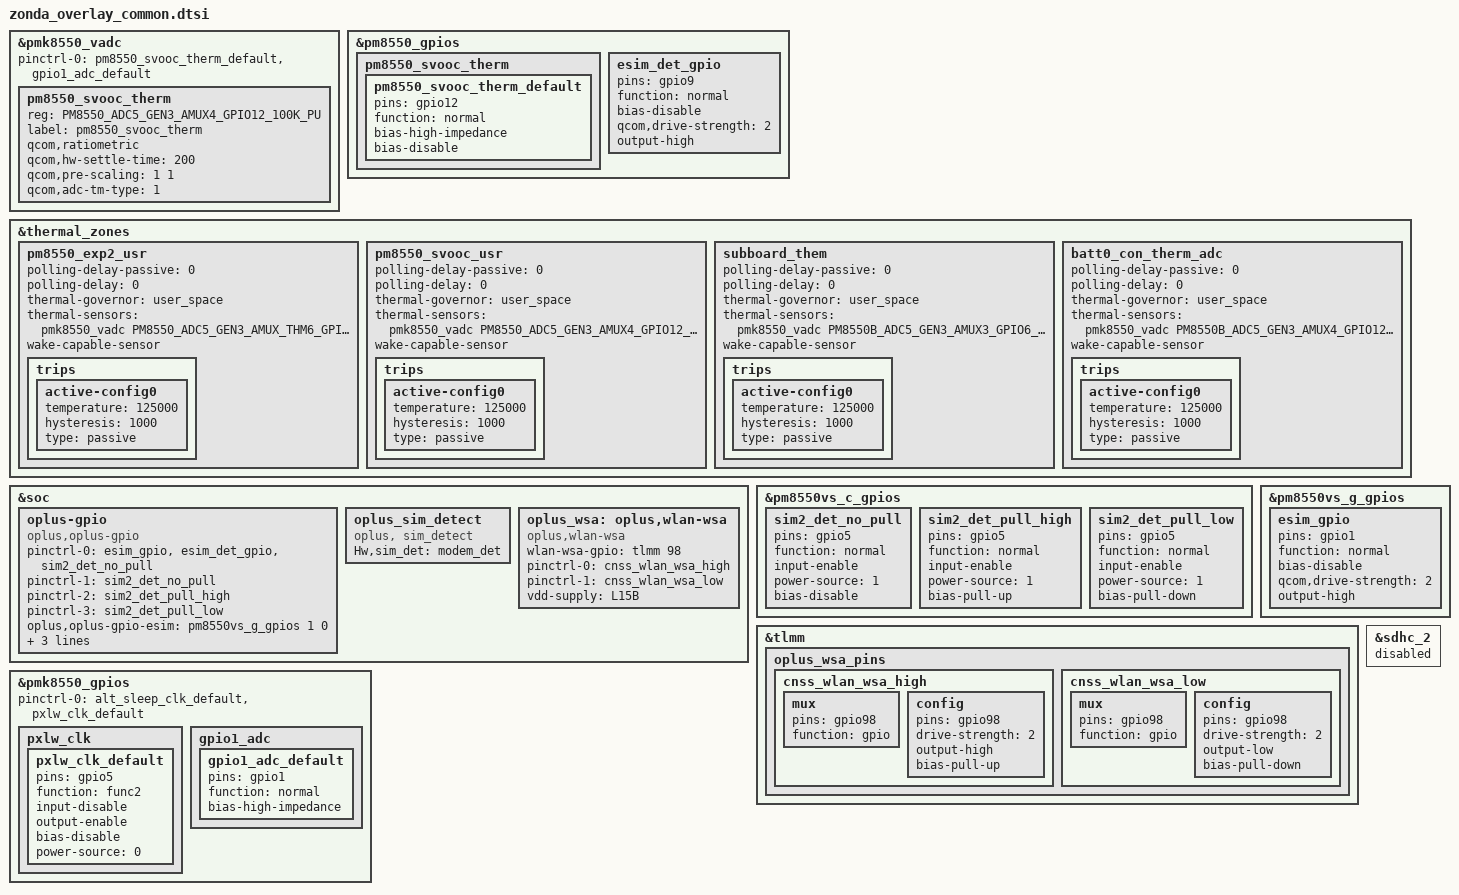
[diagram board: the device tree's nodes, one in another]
// Add the thermistors of explorer and svooc
&pmk8550_vadc {
	pinctrl-0 = <&pm8550_svooc_therm_default &gpio1_adc_default>;
	pinctrl-names = "default";

	pm8550_svooc_therm {
		reg = <PM8550_ADC5_GEN3_AMUX4_GPIO12_100K_PU>;
		label = "pm8550_svooc_therm";
		qcom,ratiometric;
		qcom,hw-settle-time = <200>;
		qcom,pre-scaling = <1 1>;
		qcom,adc-tm-type = <1>;
	};
};

&pm8550_gpios {
	pm8550_svooc_therm {
		pm8550_svooc_therm_default: pm8550_svooc_therm_default {
			pins = "gpio12";
			function = "normal"; //normal
			bias-high-impedance;
			bias-disable;
		};
	};
};
/*
&pmk8550_vadc {
	pm8550_exp2_therm {
		reg = <PM8550_ADC5_GEN3_AMUX_THM6_GPIO2_100K_PU>;
		label = "pm8550_exp2_therm";
		qcom,ratiometric;
		qcom,hw-settle-time = <200>;
		qcom,pre-scaling = <1 1>;
		qcom,adc-tm-type = <1>;
	};
};
*/
&thermal_zones {
	pm8550_exp2_usr {
		polling-delay-passive = <0>;
		polling-delay = <0>;
		thermal-governor = "user_space";
		thermal-sensors = <&pmk8550_vadc PM8550_ADC5_GEN3_AMUX_THM6_GPIO2_100K_PU>;
		wake-capable-sensor;
		trips {
			active-config0 {
				temperature = <125000>;
				hysteresis = <1000>;
				type = "passive";
			};
		};
	};

	pm8550_svooc_usr {
		polling-delay-passive = <0>;
		polling-delay = <0>;
		thermal-governor = "user_space";
		thermal-sensors = <&pmk8550_vadc PM8550_ADC5_GEN3_AMUX4_GPIO12_100K_PU>;
		wake-capable-sensor;
		trips {
			active-config0 {
				temperature = <125000>;
				hysteresis = <1000>;
				type = "passive";
			};
		};
	};
};

//#ifdef OPLUS_FEATURE_CHG_BASIC
&thermal_zones {
	subboard_them {
		polling-delay-passive = <0>;
		polling-delay = <0>;
		thermal-governor = "user_space";
		thermal-sensors = <&pmk8550_vadc PM8550B_ADC5_GEN3_AMUX3_GPIO6_100K_PU>;
		wake-capable-sensor;
		trips {
			active-config0 {
				temperature = <125000>;
				hysteresis = <1000>;
				type = "passive";
			};
		};
	};

	batt0_con_therm_adc {
		polling-delay-passive = <0>;
		polling-delay = <0>;
		thermal-governor = "user_space";
		thermal-sensors = <&pmk8550_vadc PM8550B_ADC5_GEN3_AMUX4_GPIO12_100K_PU>;
		wake-capable-sensor;
		trips {
			active-config0 {
				temperature = <125000>;
				hysteresis = <1000>;
				type = "passive";
			};
		};
	};
};
//#endif /* OPLUS_FEATURE_CHG_BASIC */

&soc {
	//#ifdef OPLUS_FEATRUE_ESIM
	oplus-gpio {
		compatible = "oplus,oplus-gpio";
		pinctrl-names = "default", "sim2_det_no_pull", "sim2_det_pull_high", "sim2_det_pull_low";
		pinctrl-0 = <&esim_gpio &esim_det_gpio &sim2_det_no_pull>;
		pinctrl-1 = <&sim2_det_no_pull>;
		pinctrl-2 = <&sim2_det_pull_high>;
		pinctrl-3 = <&sim2_det_pull_low>;
		oplus,oplus-gpio-esim = <&pm8550vs_g_gpios 1 0>;
		oplus,oplus-esim-det = <&pm8550_gpios 9 0>;
		oplus,oplus-sim2-det = <&pm8550vs_c_gpios 5 0>;
		oplus,uim-reset-pin = "modem_solution";
	};
	//#endif /* OPLUS_FEATRUE_ESIM */
	oplus_sim_detect {
		compatible = "oplus, sim_detect";
		Hw,sim_det = "modem_det";
	};
};

&pm8550vs_c_gpios {
	sim2_det_no_pull: sim2_det_no_pull {
			pins = "gpio5";
			function = "normal";
			input-enable;
			power-source = <1>;
			bias-disable;
	};

	sim2_det_pull_high: sim2_det_pull_high {
			pins = "gpio5";
			function = "normal";
			input-enable;
			power-source = <1>;
			bias-pull-up;
	};

	sim2_det_pull_low: sim2_det_pull_low {
			pins = "gpio5";
			function = "normal";
			input-enable;
			power-source = <1>;
			bias-pull-down;
	};
};

&pm8550vs_g_gpios {
	esim_gpio: esim_gpio  {
			pins = "gpio1";
			function = "normal";
			bias-disable; /* NO pull */
			qcom,drive-strength = <2>; /* 2 MA */
			output-high;
	};
};

&pm8550_gpios {
	esim_det_gpio: esim_det_gpio {
			pins = "gpio9";
			function = "normal";
			bias-disable; /* NO pull */
			qcom,drive-strength = <2>; /* 2 MA */
			output-high;
	};
};

//#ifdef OPLUS_FEATURE_WIFI_SMARTANTENNA
&tlmm {
	oplus_wsa_pins {
                cnss_wlan_wsa_high: cnss_wlan_wsa_high {
                        mux {
                                pins = "gpio98";
                                function = "gpio";
                        };

                        config {
                                pins = "gpio98";
                                drive-strength = <2>;
                                output-high;
                                bias-pull-up;
                        };
                };

                cnss_wlan_wsa_low: cnss_wlan_wsa_low {
                        mux {
                                pins = "gpio98";
                                function = "gpio";
                        };

                        config {
                                pins = "gpio98";
                                drive-strength = <2>;
                                output-low;
                                bias-pull-down;
                        };
                };
        };
};

&sdhc_2 {
	status = "disabled";
};

&soc {
	oplus_wsa: oplus,wlan-wsa {
		compatible = "oplus,wlan-wsa";
		wlan-wsa-gpio = <&tlmm 98 0>;
		pinctrl-names = "cnss_wlan_wsa_high", "cnss_wlan_wsa_low";
		pinctrl-0 = <&cnss_wlan_wsa_high>;
		pinctrl-1 = <&cnss_wlan_wsa_low>;
		vdd-supply = <&L15B>;
	};
};
//#endif /* OPLUS_FEATURE_WIFI_SMARTANTENNA */

/* #if defined(CONFIG_PXLW_IRIS) */
&pmk8550_gpios {
	/delete-property/ pinctrl-0;
	pinctrl-0 = <&alt_sleep_clk_default &pxlw_clk_default>;
	pinctrl-names = "default";

	pxlw_clk {
		pxlw_clk_default: pxlw_clk_default {
			pins = "gpio5";
			function = "func2";
			input-disable;
			output-enable;
			bias-disable;
			power-source = <0>;
		};
	};
};
/* #endif */

&pmk8550_gpios {
	gpio1_adc {
		gpio1_adc_default: gpio1_adc_default {
			pins = "gpio1";
			function = "normal";
			bias-high-impedance; /* DISABLE GPIO1 for ADC*/
		};
	};
};
